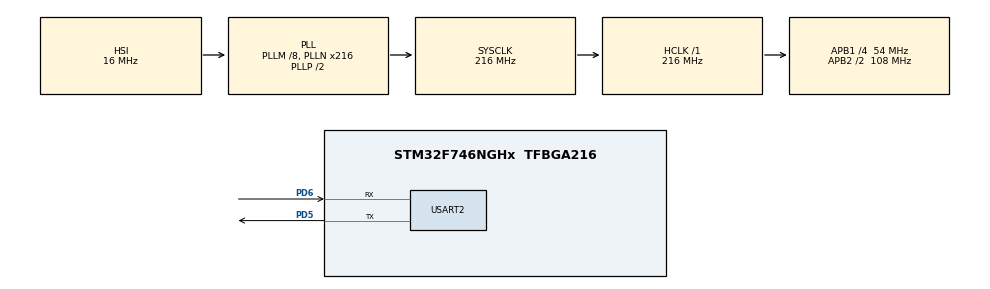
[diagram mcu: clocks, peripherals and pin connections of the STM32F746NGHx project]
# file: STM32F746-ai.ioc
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CORTEX_M7.CPU_DCache=Enabled
CORTEX_M7.CPU_ICache=Enabled
Mcu.Family=STM32F7
Mcu.Name=STM32F746NGHx
Mcu.Package=TFBGA216
NVIC.PriorityGroup=NVIC_PRIORITYGROUP_4
NVIC.USART2_IRQn=true\:0\:0\:false\:true\:true\:1\:true\:true\:true
PC14/OSC32_IN.Mode=LSE-External-Oscillator
PC14/OSC32_IN.Signal=RCC_OSC32_IN
PC15/OSC32_OUT.Mode=LSE-External-Oscillator
PC15/OSC32_OUT.Signal=RCC_OSC32_OUT
PD5.Mode=Asynchronous
PD5.Signal=USART2_TX
PD6.Mode=Asynchronous
PD6.Signal=USART2_RX
ProjectManager.HeapSize=0x800
ProjectManager.StackSize=0x800
ProjectManager.TargetToolchain=STM32CubeIDE
RCC.AHBFreq_Value=216000000
RCC.APB1CLKDivider=RCC_HCLK_DIV4
RCC.APB1Freq_Value=54000000
RCC.APB1TimFreq_Value=108000000
RCC.APB2CLKDivider=RCC_HCLK_DIV2
RCC.APB2Freq_Value=108000000
RCC.APB2TimFreq_Value=216000000
RCC.CortexFreq_Value=216000000
RCC.HCLKFreq_Value=216000000
RCC.HSE_VALUE=8000000
RCC.HSI_VALUE=16000000
RCC.PLLM=8
RCC.PLLN=216
RCC.RTCClockSelection=RCC_RTCCLKSOURCE_LSE
RCC.SYSCLKFreq_VALUE=216000000
RCC.SYSCLKSource=RCC_SYSCLKSOURCE_PLLCLK
RCC.USBFreq_Value=216000000
RCC.VCOOutputFreq_Value=432000000
STMicroelectronics.X-CUBE-AI.5.1.2.ActivationBufferSizeList=36
STMicroelectronics.X-CUBE-AI.5.1.2.ActivationBuffers=pool0
STMicroelectronics.X-CUBE-AI.5.1.2.ActivationNames=pool0
STMicroelectronics.X-CUBE-AI.5.1.2.ActivationSizes=AI_SINE_MODEL2_DATA_ACTIVATION_1_SIZE
STMicroelectronics.X-CUBE-AI.5.1.2.HeapSize=0x800
STMicroelectronics.X-CUBE-AI.5.1.2.InternalRamActivationBufferMaxSize=AI_SINE_MODEL2_DATA_ACTIVATIONS_SIZE
STMicroelectronics.X-CUBE-AI.5.1.2.LatestDirectoryUsed-58772da9f3f3dc2f8b55546c2dcc35f8d2e11a6094cba69f72e775c21cb2a9c6=D\:\\ME program\\2017-PhD\\01_research\\02Study\\34_ballon_like_cover\\DeepLearing\\TACTS\\TensorflowLite
STMicroelectronics.X-CUBE-AI.5.1.2.MaximumNumberOfInputLayer=1
STMicroelectronics.X-CUBE-AI.5.1.2.MaximumNumberOfOutputLayer=1
STMicroelectronics.X-CUBE-AI.5.1.2.MaximumSizeOfInputLayer=1
STMicroelectronics.X-CUBE-AI.5.1.2.MaximumSizeOfOutputLayer=AI_SINE_MODEL2_OUT_1_SIZE_BYTES
STMicroelectronics.X-CUBE-AI.5.1.2.ModelActualCompression-58772da9f3f3dc2f8b55546c2dcc35f8d2e11a6094cba69f72e775c21cb2a9c6=0.0
STMicroelectronics.X-CUBE-AI.5.1.2.ModelCompression-58772da9f3f3dc2f8b55546c2dcc35f8d2e11a6094cba69f72e775c21cb2a9c6=1
STMicroelectronics.X-CUBE-AI.5.1.2.ModelFlashOccupation-58772da9f3f3dc2f8b55546c2dcc35f8d2e11a6094cba69f72e775c21cb2a9c6=740
STMicroelectronics.X-CUBE-AI.5.1.2.ModelHashList=58772da9f3f3dc2f8b55546c2dcc35f8d2e11a6094cba69f72e775c21cb2a9c6
STMicroelectronics.X-CUBE-AI.5.1.2.ModelKind-58772da9f3f3dc2f8b55546c2dcc35f8d2e11a6094cba69f72e775c21cb2a9c6=TFLITE
STMicroelectronics.X-CUBE-AI.5.1.2.ModelMacc-58772da9f3f3dc2f8b55546c2dcc35f8d2e11a6094cba69f72e775c21cb2a9c6=548
STMicroelectronics.X-CUBE-AI.5.1.2.ModelName-58772da9f3f3dc2f8b55546c2dcc35f8d2e11a6094cba69f72e775c21cb2a9c6=sine_model2
STMicroelectronics.X-CUBE-AI.5.1.2.ModelNameList=sine_model2
STMicroelectronics.X-CUBE-AI.5.1.2.ModelRamOccupation-58772da9f3f3dc2f8b55546c2dcc35f8d2e11a6094cba69f72e775c21cb2a9c6=36
STMicroelectronics.X-CUBE-AI.5.1.2.ModelStructureFile-58772da9f3f3dc2f8b55546c2dcc35f8d2e11a6094cba69f72e775c21cb2a9c6=D\:\\ME program\\2017-PhD\\01_research\\02Study\\34_ballon_like_cover\\DeepLearing\\TACTS\\TensorflowLite\\sine_model_quantized.tflite
STMicroelectronics.X-CUBE-AI.5.1.2.ModelType-58772da9f3f3dc2f8b55546c2dcc35f8d2e11a6094cba69f72e775c21cb2a9c6=Saved model
STMicroelectronics.X-CUBE-AI.5.1.2.ReadyForCodeGeneration=true
STMicroelectronics.X-CUBE-AI.5.1.2.StackSize=0x800
STMicroelectronics.X-CUBE-AI.5.1.2.WorkingBufferStartAddrList=0xFFFFFFFF
STMicroelectronics.X-CUBE-AI.5.1.2.XAaCUBEAaAICcArtificialOoIntelligenceJjCore=true
STMicroelectronics.X-CUBE-AI.5.1.2.copyWeightToRam=false
STMicroelectronics.X-CUBE-AI.5.1.2.copyWeightToRam-58772da9f3f3dc2f8b55546c2dcc35f8d2e11a6094cba69f72e775c21cb2a9c6=false
STMicroelectronics.X-CUBE-AI.5.1.2.customLayerConfigEnabled=false
STMicroelectronics.X-CUBE-AI.5.1.2.customLayerConfigEnabled-58772da9f3f3dc2f8b55546c2dcc35f8d2e11a6094cba69f72e775c21cb2a9c6=false
STMicroelectronics.X-CUBE-AI.5.1.2.noOnnxIoTranspose=false
STMicroelectronics.X-CUBE-AI.5.1.2.noOnnxIoTranspose-58772da9f3f3dc2f8b55546c2dcc35f8d2e11a6094cba69f72e775c21cb2a9c6=false
STMicroelectronics.X-CUBE-AI.5.1.2.useInputAllocation=true
STMicroelectronics.X-CUBE-AI.5.1.2.useInputAllocation-58772da9f3f3dc2f8b55546c2dcc35f8d2e11a6094cba69f72e775c21cb2a9c6=true
STMicroelectronics.X-CUBE-AI.5.1.2.useOutputAllocation=true
STMicroelectronics.X-CUBE-AI.5.1.2.useOutputAllocation-58772da9f3f3dc2f8b55546c2dcc35f8d2e11a6094cba69f72e775c21cb2a9c6=true
TIM6.Prescaler=216-1
USART2.VirtualMode-Asynchronous=VM_ASYNC
VP_CRC_VS_CRC.Mode=CRC_Activate
VP_RTC_VS_RTC_Activate.Mode=RTC_Enabled
VP_STMicroelectronics.X-CUBE-AI_VS_ArtificialOoIntelligenceJjXAaCUBEAaAI_5.1.2.Mode=ArtificialOoIntelligenceJjXAaCUBEAaAI
VP_TIM6_VS_ClockSourceINT.Mode=Enable_Timer
board=custom

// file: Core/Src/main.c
/* USER CODE BEGIN Header */
/**
  ******************************************************************************
  * @file           : main.c
  * @brief          : Main program body
  ******************************************************************************
  * @attention
  *
  * Copyright (c) 2023 STMicroelectronics.
  * All rights reserved.
  *
  * This software is licensed under terms that can be found in the LICENSE file
  * in the root directory of this software component.
  * If no LICENSE file comes with this software, it is provided AS-IS.
  *
  ******************************************************************************
  */
/* USER CODE END Header */
#include "main.h"

/* USER CODE BEGIN Includes */
#include <stdio.h>

#include "ai_datatypes_defines.h"
#include "ai_platform.h"
#include "sine_model2.h"
#include "sine_model2_data.h"

/* USER CODE END Includes */

CRC_HandleTypeDef hcrc;

RTC_HandleTypeDef hrtc;

TIM_HandleTypeDef htim6;

UART_HandleTypeDef huart2;

/* USER CODE BEGIN PV */
uint8_t tx_buffer[27]="Welcome to Binary!/n/r";
/* USER CODE END PV */

void SystemClock_Config(void);
static void MX_GPIO_Init(void);
static void MX_CRC_Init(void);
static void MX_TIM6_Init(void);
static void MX_RTC_Init(void);
static void MX_USART2_UART_Init(void);
static void MX_NVIC_Init(void);

int main(void)
{
  /* USER CODE BEGIN 1 */
	  char buf[50];
	  int buf_len = 0;
	  ai_error ai_err;
	  ai_i32 nbatch;
	  uint32_t timestamp;
	  float y_val;

	  // Chunk of memory used to hold intermediate values for neural network
	  AI_ALIGNED(4) ai_u8 activations[AI_SINE_MODEL2_DATA_ACTIVATIONS_SIZE];

	  // Buffers used to store input and output tensors
	  AI_ALIGNED(4) ai_i8 in_data[AI_SINE_MODEL2_IN_1_SIZE_BYTES];
	  AI_ALIGNED(4) ai_i8 out_data[AI_SINE_MODEL2_OUT_1_SIZE_BYTES];

	  // Pointer to our model
	  ai_handle sine_model2 = AI_HANDLE_NULL;

	  // Initialize wrapper structs that hold pointers to data and info about the
	  // data (tensor height, width, channels)
	  ai_buffer ai_input[AI_SINE_MODEL2_IN_NUM] = AI_SINE_MODEL2_IN;
	  ai_buffer ai_output[AI_SINE_MODEL2_OUT_NUM] = AI_SINE_MODEL2_OUT;

	  // Set working memory and get weights/biases from model
	  ai_network_params ai_params = {
	    AI_SINE_MODEL2_DATA_WEIGHTS(ai_sine_model2_data_weights_get()),
	    AI_SINE_MODEL2_DATA_ACTIVATIONS(activations)
	  };

	  // Set pointers wrapper structs to our data buffers
	  ai_input[0].n_batches = 1;
	  ai_input[0].data = AI_HANDLE_PTR(in_data);
	  ai_output[0].n_batches = 1;
	  ai_output[0].data = AI_HANDLE_PTR(out_data);

  /* USER CODE END 1 */

  /* Enable I-Cache---------------------------------------------------------*/
  SCB_EnableICache();

  /* Enable D-Cache---------------------------------------------------------*/
  SCB_EnableDCache();

  /* MCU Configuration--------------------------------------------------------*/

  /* Reset of all peripherals, Initializes the Flash interface and the Systick. */
  HAL_Init();

  /* Configure the system clock */
  SystemClock_Config();

  /* Initialize all configured peripherals */
  MX_GPIO_Init();
  MX_CRC_Init();
  MX_TIM6_Init();
  MX_RTC_Init();
  MX_USART2_UART_Init();

  /* Initialize interrupts */
  MX_NVIC_Init();
  /* USER CODE BEGIN 2 */
  HAL_TIM_Base_Start(&htim6);

    // Greetings!
    buf_len = sprintf(buf, "\r\n\r\nSTM32 X-Cube-AI test\r\n");
    HAL_UART_Transmit(&huart2, (uint8_t *)buf, buf_len, 100);

    // Create instance of neural network
    ai_err = ai_sine_model2_create(&sine_model2, AI_SINE_MODEL2_DATA_CONFIG);
    if (ai_err.type != AI_ERROR_NONE)
    {
      buf_len = sprintf(buf, "Error: could not create NN instance\r\n");
      HAL_UART_Transmit(&huart2, (uint8_t *)buf, buf_len, 100);

      //while(1);
    }

    // Initialize neural network
    if (!ai_sine_model2_init(sine_model2, &ai_params))
    {
      buf_len = sprintf(buf, "Error: could not initialize NN\r\n");
      HAL_UART_Transmit(&huart2, (uint8_t *)buf, buf_len, 100);
      //while(1);
    }
  /* USER CODE END 2 */

  /* Infinite loop */
  /* USER CODE BEGIN WHILE */
  while (1)
  {

      HAL_UART_Transmit(&huart2, (uint8_t *)buf, sprintf(buf, "Hi\r\n"), 100);

	  // Fill input buffer (use test value)
	      for (uint32_t i = 0; i < AI_SINE_MODEL2_IN_1_SIZE; i++)
	      {
	        ((ai_float *)in_data)[i] = (ai_float)2.0f;
	      }

	      // Get current timestamp
	      timestamp = htim6.Instance->CNT;

	      // Perform inference
	      nbatch = ai_sine_model2_run(sine_model2, &ai_input[0], &ai_output[0]);
	      if (nbatch != 1) {
	        HAL_UART_Transmit(&huart2, (uint8_t *)buf, sprintf(buf, "Error: could not run inference\r\n"), 100);

	      }

	      // Read output (predicted y) of neural network
	      y_val = ((float *)out_data)[0];

	      // Print output of neural network along with inference time (microseconds)
	      buf_len = sprintf(buf,
	                        "Output: %f | Duration: %lu\r\n",
	                        y_val,
	                        htim6.Instance->CNT - timestamp);
	      HAL_UART_Transmit(&huart2, (uint8_t *)buf, buf_len, 100);

	      // Wait before doing it again
	      HAL_Delay(500);
    /* USER CODE END WHILE */

    /* USER CODE BEGIN 3 */
	      HAL_UART_Transmit(&huart2, tx_buffer, 27, 100);
	      HAL_Delay(500);

  }
  /* USER CODE END 3 */
}

void SystemClock_Config(void)
{
  RCC_OscInitTypeDef RCC_OscInitStruct = {0};
  RCC_ClkInitTypeDef RCC_ClkInitStruct = {0};

  /** Configure LSE Drive Capability
  */
  HAL_PWR_EnableBkUpAccess();
  __HAL_RCC_LSEDRIVE_CONFIG(RCC_LSEDRIVE_LOW);

  /** Configure the main internal regulator output voltage
  */
  __HAL_RCC_PWR_CLK_ENABLE();
  __HAL_PWR_VOLTAGESCALING_CONFIG(PWR_REGULATOR_VOLTAGE_SCALE1);

  /** Initializes the RCC Oscillators according to the specified parameters
  * in the RCC_OscInitTypeDef structure.
  */
  RCC_OscInitStruct.OscillatorType = RCC_OSCILLATORTYPE_HSI|RCC_OSCILLATORTYPE_LSE;
  RCC_OscInitStruct.LSEState = RCC_LSE_ON;
  RCC_OscInitStruct.HSIState = RCC_HSI_ON;
  RCC_OscInitStruct.HSICalibrationValue = RCC_HSICALIBRATION_DEFAULT;
  RCC_OscInitStruct.PLL.PLLState = RCC_PLL_ON;
  RCC_OscInitStruct.PLL.PLLSource = RCC_PLLSOURCE_HSI;
  RCC_OscInitStruct.PLL.PLLM = 8;
  RCC_OscInitStruct.PLL.PLLN = 216;
  RCC_OscInitStruct.PLL.PLLP = RCC_PLLP_DIV2;
  RCC_OscInitStruct.PLL.PLLQ = 2;
  if (HAL_RCC_OscConfig(&RCC_OscInitStruct) != HAL_OK)
  {
    Error_Handler();
  }

  /** Activate the Over-Drive mode
  */
  if (HAL_PWREx_EnableOverDrive() != HAL_OK)
  {
    Error_Handler();
  }

  /** Initializes the CPU, AHB and APB buses clocks
  */
  RCC_ClkInitStruct.ClockType = RCC_CLOCKTYPE_HCLK|RCC_CLOCKTYPE_SYSCLK
                              |RCC_CLOCKTYPE_PCLK1|RCC_CLOCKTYPE_PCLK2;
  RCC_ClkInitStruct.SYSCLKSource = RCC_SYSCLKSOURCE_PLLCLK;
  RCC_ClkInitStruct.AHBCLKDivider = RCC_SYSCLK_DIV1;
  RCC_ClkInitStruct.APB1CLKDivider = RCC_HCLK_DIV4;
  RCC_ClkInitStruct.APB2CLKDivider = RCC_HCLK_DIV2;

  if (HAL_RCC_ClockConfig(&RCC_ClkInitStruct, FLASH_LATENCY_7) != HAL_OK)
  {
    Error_Handler();
  }
}

/**
  * @brief NVIC Configuration.
  * @retval None
  */
static void MX_NVIC_Init(void)
{
  /* USART2_IRQn interrupt configuration */
  HAL_NVIC_SetPriority(USART2_IRQn, 0, 0);
  HAL_NVIC_EnableIRQ(USART2_IRQn);
}

static void MX_CRC_Init(void)
{

  hcrc.Instance = CRC;
  hcrc.Init.DefaultPolynomialUse = DEFAULT_POLYNOMIAL_ENABLE;
  hcrc.Init.DefaultInitValueUse = DEFAULT_INIT_VALUE_ENABLE;
  hcrc.Init.InputDataInversionMode = CRC_INPUTDATA_INVERSION_NONE;
  hcrc.Init.OutputDataInversionMode = CRC_OUTPUTDATA_INVERSION_DISABLE;
  hcrc.InputDataFormat = CRC_INPUTDATA_FORMAT_BYTES;
  if (HAL_CRC_Init(&hcrc) != HAL_OK)
  {
    Error_Handler();
  }

}

static void MX_RTC_Init(void)
{

  /** Initialize RTC Only
  */
  hrtc.Instance = RTC;
  hrtc.Init.HourFormat = RTC_HOURFORMAT_24;
  hrtc.Init.AsynchPrediv = 127;
  hrtc.Init.SynchPrediv = 255;
  hrtc.Init.OutPut = RTC_OUTPUT_DISABLE;
  hrtc.Init.OutPutPolarity = RTC_OUTPUT_POLARITY_HIGH;
  hrtc.Init.OutPutType = RTC_OUTPUT_TYPE_OPENDRAIN;
  if (HAL_RTC_Init(&hrtc) != HAL_OK)
  {
    Error_Handler();
  }

}

static void MX_TIM6_Init(void)
{

  TIM_MasterConfigTypeDef sMasterConfig = {0};

  htim6.Instance = TIM6;
  htim6.Init.Prescaler = 216-1;
  htim6.Init.CounterMode = TIM_COUNTERMODE_UP;
  htim6.Init.Period = 65535;
  htim6.Init.AutoReloadPreload = TIM_AUTORELOAD_PRELOAD_DISABLE;
  if (HAL_TIM_Base_Init(&htim6) != HAL_OK)
  {
    Error_Handler();
  }
  sMasterConfig.MasterOutputTrigger = TIM_TRGO_RESET;
  sMasterConfig.MasterSlaveMode = TIM_MASTERSLAVEMODE_DISABLE;
  if (HAL_TIMEx_MasterConfigSynchronization(&htim6, &sMasterConfig) != HAL_OK)
  {
    Error_Handler();
  }

}

static void MX_USART2_UART_Init(void)
{

  huart2.Instance = USART2;
  huart2.Init.BaudRate = 115200;
  huart2.Init.WordLength = UART_WORDLENGTH_8B;
  huart2.Init.StopBits = UART_STOPBITS_1;
  huart2.Init.Parity = UART_PARITY_NONE;
  huart2.Init.Mode = UART_MODE_TX_RX;
  huart2.Init.HwFlowCtl = UART_HWCONTROL_NONE;
  huart2.Init.OverSampling = UART_OVERSAMPLING_16;
  huart2.Init.OneBitSampling = UART_ONE_BIT_SAMPLE_DISABLE;
  huart2.AdvancedInit.AdvFeatureInit = UART_ADVFEATURE_NO_INIT;
  if (HAL_UART_Init(&huart2) != HAL_OK)
  {
    Error_Handler();
  }

}

static void MX_GPIO_Init(void)
{

  /* GPIO Ports Clock Enable */
  __HAL_RCC_GPIOD_CLK_ENABLE();
  __HAL_RCC_GPIOC_CLK_ENABLE();

}

void Error_Handler(void)
{
  __disable_irq();
  while (1)
  {
  }
}
